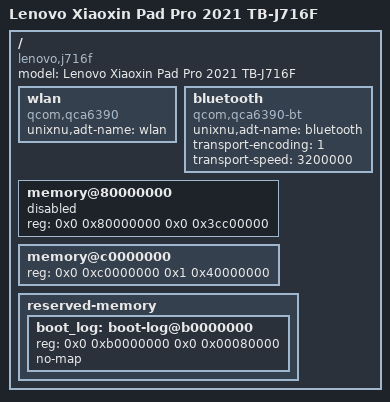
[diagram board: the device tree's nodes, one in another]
/dts-v1/;
/include/ "sm8250.dtsi"

/ {
    model = "Lenovo Xiaoxin Pad Pro 2021 TB-J716F";
    compatible = "lenovo,j716f", "qcom,sm8250";

    // Export QCA6390 wireless ADT nodes before launchd evaluates wifid / bluetoothd conditions.
    wlan {
        compatible = "qcom,qca6390";
        unixnu,adt-name = "wlan";
        status = "okay";
    };

    bluetooth {
        device_type = "bluetooth";
        compatible = "qcom,qca6390-bt";
        unixnu,adt-name = "bluetooth";
        transport-encoding = <1>;
        transport-speed = <3200000>;
        status = "okay";
    };

    // Android runtime FDT: DTB index 0 + DTBO index 1, batch 20261111-231708.
    // The common ADT converter accepts exactly ONE enabled contiguous memory
    // range. Keep the low bank here as inventory, disabled for that converter.
    memory@80000000 {
        device_type = "memory";
        reg = <0x0 0x80000000 0x0 0x3cc00000>;
        status = "disabled";
    };

    // Candidate high bank: 5 GiB; NOT the physical SKU capacity or a verified
    // XNU allocation. The device is 6 GiB class with a 52 MiB gap below this bank.
    // UEFI heap/FD/guard and loader allocations must be subtracted/owned later.
    memory@c0000000 {
        device_type = "memory";
        reg = <0x0 0xc0000000 0x1 0x40000000>;
        status = "okay";
    };

    reserved-memory {
        #address-cells = <2>;
        #size-cells = <2>;
        ranges;

        // Exact stock/runtime reservation, not the old 1 MiB assumption.
        boot_log: boot-log@b0000000 {
            reg = <0x0 0xb0000000 0x0 0x00080000>;
            no-map;
        };
    };
};

// All 8 Kryo 585 cores (4x A55 E + 4x A77 P) from sm8250.dtsi are enabled in the ADT;
// secondary CPU bring-up remains safely opt-in via the ArmCpu `smp=1` boot-arg.

// This is an XNU hardware-description draft, NOT the Android boot image FDT.
// Other firmware reservations, GOP, UFS/SMMU and peripheral providers are
// deliberately pending. Their measured facts live in docs/hardware-baseline.md.
